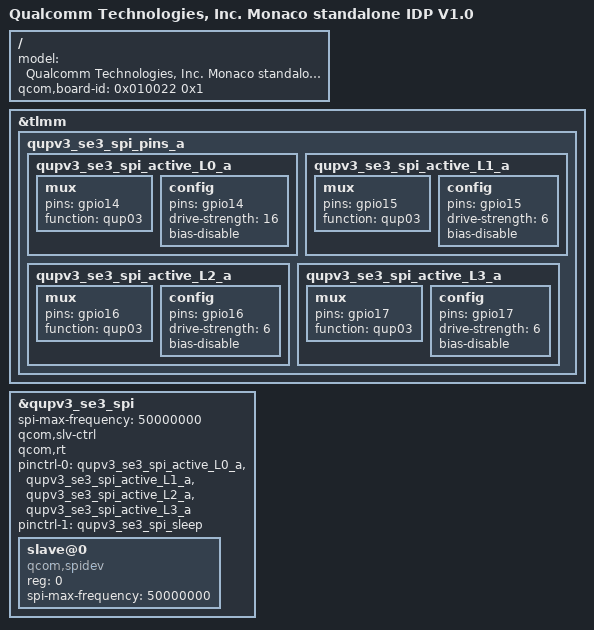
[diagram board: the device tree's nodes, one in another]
/dts-v1/;
/plugin/;

#include "monaco-standalone-idp-v1.dtsi"

/ {
	model = "Qualcomm Technologies, Inc. Monaco standalone IDP V1.0";
	qcom,board-id = <0x010022 0x1>;
};

&tlmm {
	qupv3_se3_spi_pins_a: qupv3_se3_spi_pins_a {
		//MISO
		qupv3_se3_spi_active_L0_a: qupv3_se3_spi_active_L0_a {
			mux {
				pins = "gpio14";
				function = "qup03";
			};

			config {
				pins = "gpio14";
				drive-strength = <16>;
				bias-disable;
			};
		};

		//MOSI
		qupv3_se3_spi_active_L1_a: qupv3_se3_spi_active_L1_a {
			mux {
				pins = "gpio15";
				function = "qup03";
			};

			config {
				pins = "gpio15";
				drive-strength = <6>;
				bias-disable;
			};
		};

		//CLK
		qupv3_se3_spi_active_L2_a: qupv3_se3_spi_active_L2_a {
			mux {
				pins = "gpio16";
				function = "qup03";
			};

			config {
				pins = "gpio16";
				drive-strength = <6>;
				bias-disable;
			};
		};

		//CS
		qupv3_se3_spi_active_L3_a: qupv3_se3_spi_active_L3_a {
			mux {
				pins = "gpio17";
				function = "qup03";
			};

			config {
				pins = "gpio17";
				drive-strength = <6>;
				bias-disable;
			};
		};

	};

};

//spi@4a8c000 work as HLOS SPI slave
&qupv3_se3_spi {
	spi-max-frequency = <50000000>;
	status = "ok";
	//work as SPI slave
	qcom,slv-ctrl;
	qcom,rt;

	pinctrl-names = "default", "sleep";
	pinctrl-0 = <&qupv3_se3_spi_active_L0_a
		&qupv3_se3_spi_active_L1_a &qupv3_se3_spi_active_L2_a
				&qupv3_se3_spi_active_L3_a>;
	pinctrl-1 = <&qupv3_se3_spi_sleep>;

	slave@0 {
		compatible = "qcom,spidev";
		reg = <0>;
		spi-max-frequency = <50000000>;
	};
};
